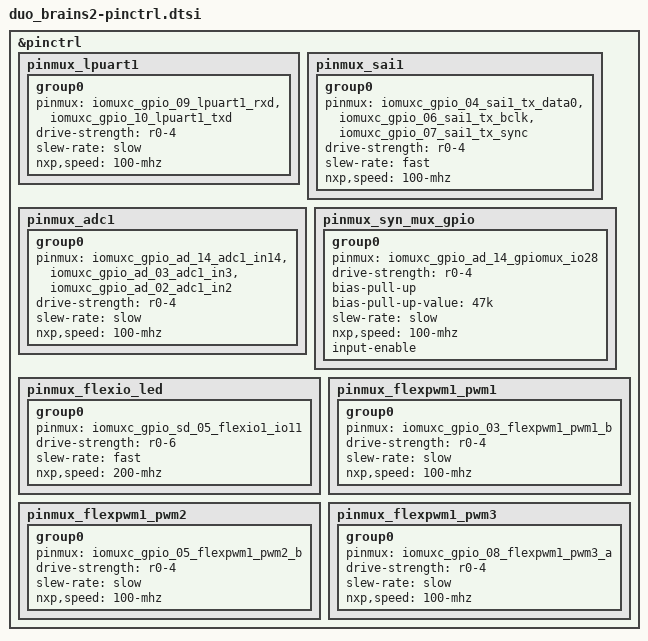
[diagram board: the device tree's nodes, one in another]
/*
 * Copyright (c) 2025 Dato Musical Instruments
 * SPDX-License-Identifier: Apache-2.0
 *
 * Pin muxing for the Dato DUO "Brains 2" main board (rev 2.1).
 *
 * The pad assignments below are transcribed from the MCUXpresso-SDK firmware
 * in brains2/: core/lib/board.h, core/boards/DUO_BRAINS_2.1/{pins,audio}.cpp,
 * core/lib/flexio_led_driver.h and core/custom_teensy_audio/output_pt8211.cpp.
 */

#include <nxp/nxp_imx/rt/mimxrt1011dae5a-pinctrl.dtsi>

&pinctrl {
	/* MIDI DIN in/out, driven at 31250 baud. */
	pinmux_lpuart1: pinmux_lpuart1 {
		group0 {
			pinmux = <&iomuxc_gpio_09_lpuart1_rxd>,
				 <&iomuxc_gpio_10_lpuart1_txd>;
			drive-strength = "r0-4";
			slew-rate = "slow";
			nxp,speed = "100-mhz";
		};
	};

	/* I2S to the PT8211 stereo DAC. No MCLK: the DAC is BCLK/WS only. */
	pinmux_sai1: pinmux_sai1 {
		group0 {
			pinmux = <&iomuxc_gpio_04_sai1_tx_data0>,
				 <&iomuxc_gpio_06_sai1_tx_bclk>,
				 <&iomuxc_gpio_07_sai1_tx_sync>;
			drive-strength = "r0-4";
			slew-rate = "fast";
			nxp,speed = "100-mhz";
		};
	};

	/*
	 * The three analog multiplexer I/O pins. All eight pots and all the
	 * momentary switches / drum pads hang off 4051-style muxes, so the
	 * whole panel is read through just these three pads.
	 */
	pinmux_adc1: pinmux_adc1 {
		group0 {
			pinmux = <&iomuxc_gpio_ad_14_adc1_in14>, /* SYN mux  */
				 <&iomuxc_gpio_ad_03_adc1_in3>,  /* SYN mux2 */
				 <&iomuxc_gpio_ad_02_adc1_in2>;  /* BRN mux  */
			drive-strength = "r0-4";
			slew-rate = "slow";
			nxp,speed = "100-mhz";
		};
	};

	/*
	 * Alternate muxing for the SYN mux I/O pad. The GLIDE and DELAY
	 * switches are read as pulled-up digital inputs, which the ADC input
	 * buffer cannot do, so the pad is re-muxed to GPIO for those two
	 * channels and back to ADC afterwards.
	 */
	pinmux_syn_mux_gpio: pinmux_syn_mux_gpio {
		group0 {
			pinmux = <&iomuxc_gpio_ad_14_gpiomux_io28>;
			drive-strength = "r0-4";
			bias-pull-up;
			bias-pull-up-value = "47k";
			slew-rate = "slow";
			nxp,speed = "100-mhz";
			input-enable;
		};
	};

	/* WS2812 / SK6812 data line, generated by FlexIO. */
	pinmux_flexio_led: pinmux_flexio_led {
		group0 {
			pinmux = <&iomuxc_gpio_sd_05_flexio1_io11>;
			drive-strength = "r0-6";
			slew-rate = "fast";
			nxp,speed = "200-mhz";
		};
	};

	/* Panel indicator LEDs, dimmed with FlexPWM. */
	pinmux_flexpwm1_pwm1: pinmux_flexpwm1_pwm1 {
		group0 {
			pinmux = <&iomuxc_gpio_03_flexpwm1_pwm1_b>;
			drive-strength = "r0-4";
			slew-rate = "slow";
			nxp,speed = "100-mhz";
		};
	};

	pinmux_flexpwm1_pwm2: pinmux_flexpwm1_pwm2 {
		group0 {
			pinmux = <&iomuxc_gpio_05_flexpwm1_pwm2_b>;
			drive-strength = "r0-4";
			slew-rate = "slow";
			nxp,speed = "100-mhz";
		};
	};

	pinmux_flexpwm1_pwm3: pinmux_flexpwm1_pwm3 {
		group0 {
			pinmux = <&iomuxc_gpio_08_flexpwm1_pwm3_a>;
			drive-strength = "r0-4";
			slew-rate = "slow";
			nxp,speed = "100-mhz";
		};
	};
};
